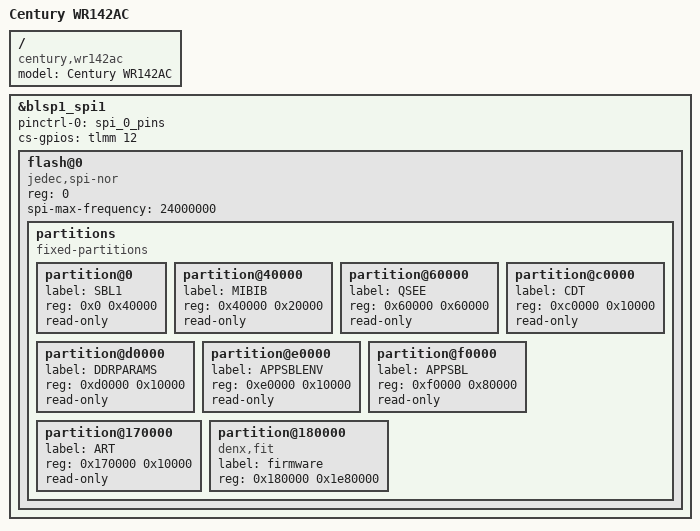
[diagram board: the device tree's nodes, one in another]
// SPDX-License-Identifier: GPL-2.0-or-later OR MIT

#include "qcom-ipq4019-wr142ac.dtsi"

/ {
	model = "Century WR142AC";
	compatible = "century,wr142ac";
};

&blsp1_spi1 {
	pinctrl-0 = <&spi_0_pins>;
	pinctrl-names = "default";
	status = "okay";
	cs-gpios = <&tlmm 12 GPIO_ACTIVE_HIGH>;

	flash@0 {
		reg = <0>;
		compatible = "jedec,spi-nor";
		spi-max-frequency = <24000000>;

		partitions {
			compatible = "fixed-partitions";
			#address-cells = <1>;
			#size-cells = <1>;

			partition@0 {
				label = "SBL1";
				reg = <0x0 0x40000>;
				read-only;
			};

			partition@40000 {
				label = "MIBIB";
				reg = <0x40000 0x20000>;
				read-only;
			};

			partition@60000 {
				label = "QSEE";
				reg = <0x60000 0x60000>;
				read-only;
			};

			partition@c0000 {
				label = "CDT";
				reg = <0xc0000 0x10000>;
				read-only;
			};

			partition@d0000 {
				label = "DDRPARAMS";
				reg = <0xd0000 0x10000>;
				read-only;
			};

			partition@e0000 {
				label = "APPSBLENV";
				reg = <0xe0000 0x10000>;
				read-only;
			};

			partition@f0000 {
				label = "APPSBL";
				reg = <0xf0000 0x80000>;
				read-only;
			};

			partition@170000 {
				label = "ART";
				reg = <0x170000 0x10000>;
				read-only;
			};

			partition@180000 {
				compatible = "denx,fit";
				label = "firmware";
				reg = <0x180000 0x1e80000>;
			};
		};
	};
};
